# nrf52 register map
Vendor: Nordic Semiconductor; Series: nrf52; File version: 1
CPU: CM4 r0p1, little endian, MPU, FPU, 3 interrupt priority bits
Registers are 32-bit, read-write, reset 0x0 unless marked. A register's access mark holds for its fields unless they carry their own. Offsets are from the block's base; [hi:lo] are bit positions; {n}, {i} and the like mark numbered series; 'fields as' and 'values as' point back to an identical list.

## TWI0 — I2C compatible Two-Wire Interface 0
Base 0x40003000; alternate view of SPIM0
Same registers: TWI1 0x40004000 (alternate view of SPIM1)
0x00 TASKS_STARTRX wo — Start TWI receive sequence
  [0] TASKS_STARTRX
0x08 TASKS_STARTTX wo — Start TWI transmit sequence
  [0] TASKS_STARTTX
0x14 TASKS_STOP wo — Stop TWI transaction
  [0] TASKS_STOP
0x1C TASKS_SUSPEND wo — Suspend TWI transaction
  [0] TASKS_SUSPEND
0x20 TASKS_RESUME wo — Resume TWI transaction
  [0] TASKS_RESUME
0x104 EVENTS_STOPPED — TWI stopped
  [0] EVENTS_STOPPED
0x108 EVENTS_RXDREADY — TWI RXD byte received
  [0] EVENTS_RXDREADY
0x11C EVENTS_TXDSENT — TWI TXD byte sent
  [0] EVENTS_TXDSENT
0x124 EVENTS_ERROR — TWI error
  [0] EVENTS_ERROR
0x138 EVENTS_BB — TWI byte boundary, generated before each byte that is sent or received
  [0] EVENTS_BB
0x148 EVENTS_SUSPENDED — TWI entered the suspended state
  [0] EVENTS_SUSPENDED
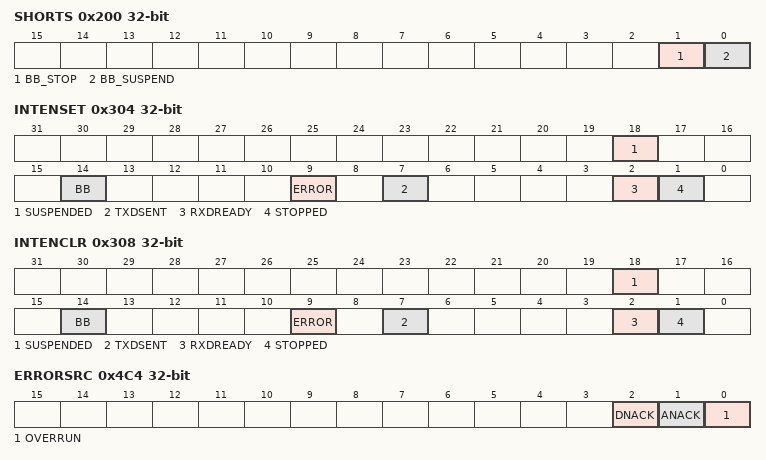
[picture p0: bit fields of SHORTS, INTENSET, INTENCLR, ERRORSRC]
0x200 SHORTS — Shortcut register
  [1] BB_STOP — Shortcut between BB event and STOP task
    0=Disabled (Disable shortcut); 1=Enabled (Enable shortcut)
  [0] BB_SUSPEND — Shortcut between BB event and SUSPEND task
    0=Disabled (Disable shortcut); 1=Enabled (Enable shortcut)
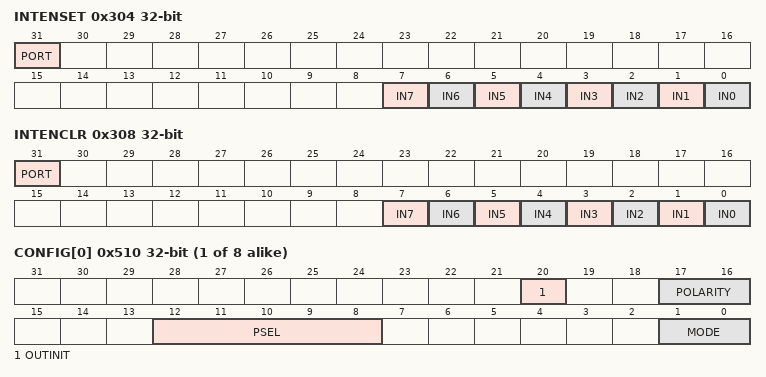
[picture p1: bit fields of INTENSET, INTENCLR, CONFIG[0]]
0x304 INTENSET — Enable interrupt
  [all] fields
    on read: 0=Disabled (Read: Disabled); 1=Enabled (Read: Enabled) | on write: 1=Set (Enable)
  [18] SUSPENDED — Write '1' to Enable interrupt for SUSPENDED event
  [14] BB — Write '1' to Enable interrupt for BB event
  [9] ERROR — Write '1' to Enable interrupt for ERROR event
  [7] TXDSENT — Write '1' to Enable interrupt for TXDSENT event
  [2] RXDREADY — Write '1' to Enable interrupt for RXDREADY event
  [1] STOPPED — Write '1' to Enable interrupt for STOPPED event
0x308 INTENCLR — Disable interrupt
  [all] fields
    on read: 0=Disabled (Read: Disabled); 1=Enabled (Read: Enabled) | on write: 1=Clear (Disable)
  [18] SUSPENDED — Write '1' to Disable interrupt for SUSPENDED event
  [14] BB — Write '1' to Disable interrupt for BB event
  [9] ERROR — Write '1' to Disable interrupt for ERROR event
  [7] TXDSENT — Write '1' to Disable interrupt for TXDSENT event
  [2] RXDREADY — Write '1' to Disable interrupt for RXDREADY event
  [1] STOPPED — Write '1' to Disable interrupt for STOPPED event
0x4C4 ERRORSRC write-1-clears — Error source
  [2] DNACK — NACK received after sending a data byte (write '1' to clear)
    on read: 0=NotPresent (Read: error not present); 1=Present (Read: error present) | on write: 1=Clear (Write: clear error on writing '1')
  [1] ANACK — NACK received after sending the address (write '1' to clear)
    values as DNACK
  [0] OVERRUN — Overrun error
    on read: 0=NotPresent (Read: no overrun occured); 1=Present (Read: overrun occured) | on write: 1=Clear (Write: clear error on writing '1')
0x500 ENABLE — Enable TWI
  [3:0] ENABLE — Enable or disable TWI
    0=Disabled (Disable TWI); 5=Enabled (Enable TWI)
0x508 PSELSCL reset 0xFFFFFFFF — Pin select for SCL
  [31:0] PSELSCL — Pin number configuration for TWI SCL signal
    0xFFFFFFFF=Disconnected
0x50C PSELSDA reset 0xFFFFFFFF — Pin select for SDA
  [31:0] PSELSDA — Pin number configuration for TWI SDA signal
    0xFFFFFFFF=Disconnected
0x518 RXD ro read-has-side-effects
  [7:0] RXD
0x51C TXD
  [7:0] TXD
0x524 FREQUENCY reset 0x4000000 — TWI frequency
  [31:0] FREQUENCY — TWI master clock frequency
    0x1980000=K100 (100 kbps); 0x4000000=K250 (250 kbps); 0x6680000=K400 (400 kbps (actual rate 410.256 kbps))
0x588 ADDRESS — Address used in the TWI transfer
  [6:0] ADDRESS

## GPIOTE — GPIO Tasks and Events
Base 0x40006000
{0x0+4i} TASKS_OUT[{i}] (i=0..7) wo — Description collection[0]: Task for writing to pin specified in CONFIG[0].PSEL. Action on pin is configured in CONFIG[0].POLARITY.
  [0] TASKS_OUT
{0x30+4i} TASKS_SET[{i}] (i=0..7) wo — Description collection[0]: Task for writing to pin specified in CONFIG[0].PSEL. Action on pin is to set it high.
  [0] TASKS_SET
{0x60+4i} TASKS_CLR[{i}] (i=0..7) wo — Description collection[0]: Task for writing to pin specified in CONFIG[0].PSEL. Action on pin is to set it low.
  [0] TASKS_CLR
{0x100+4i} EVENTS_IN[{i}] (i=0..7) — Description collection[0]: Event generated from pin specified in CONFIG[0].PSEL
  [0] EVENTS_IN
0x17C EVENTS_PORT — Event generated from multiple input GPIO pins with SENSE mechanism enabled
  [0] EVENTS_PORT
0x304 INTENSET — Enable interrupt
  [all] fields
    on read: 0=Disabled (Read: Disabled); 1=Enabled (Read: Enabled) | on write: 1=Set (Enable)
  [31] PORT — Write '1' to Enable interrupt for PORT event
  [n] IN{n} (n=0..7) — Write '1' to Enable interrupt for IN[{n}] event
0x308 INTENCLR — Disable interrupt
  [all] fields
    on read: 0=Disabled (Read: Disabled); 1=Enabled (Read: Enabled) | on write: 1=Clear (Disable)
  [31] PORT — Write '1' to Disable interrupt for PORT event
  [n] IN{n} (n=0..7) — Write '1' to Disable interrupt for IN[{n}] event
{0x510+4i} CONFIG[{i}] (i=0..7) — Description collection[0]: Configuration for OUT[n], SET[n] and CLR[n] tasks and IN[n] event
  [20] OUTINIT — When in task mode: Initial value of the output when the GPIOTE channel is configured. When in event mode: No effect.
    0=Low (Task mode: Initial value of pin before task triggering is low); 1=High (Task mode: Initial value of pin before task triggering is high)
  [17:16] POLARITY — When In task mode: Operation to be performed on output when OUT[n] task is triggered. When In event mode: Operation on input that shall trigger IN[n] event.
    0=None (Task mode: No effect on pin from OUT[n] task. Event mode: no IN[n] event generated on pin activity.); 1=LoToHi (Task mode: Set pin from OUT[n] task. Event mode: Generate IN[n] event when rising edge on pin.); 2=HiToLo (Task mode: Clear pin from OUT[n] task. Event mode: Generate IN[n] event when falling edge on pin.); 3=Toggle (Task mode: Toggle pin from OUT[n]. Event mode: Generate IN[n] when any change on pin.)
  [12:8] PSEL — GPIO number associated with SET[n], CLR[n] and OUT[n] tasks and IN[n] event
  [1:0] MODE
    0=Disabled. Pin specified by PSEL will not be acquired by the GPIOTE module.; 1=Event mode; 3=Task mode
